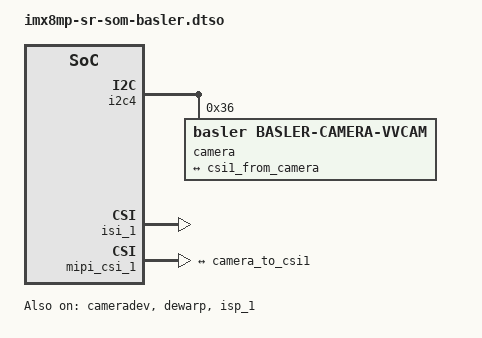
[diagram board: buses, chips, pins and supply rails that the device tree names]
// SPDX-License-Identifier: (GPL-2.0+ OR MIT)
/*
 * Copyright 2025 Josua Mayer <josua@solid-run.com>
 *
 * Overlay for Basler camera attached to SolidRun SoM camera connector.
 */

/dts-v1/;
/plugin/;

&i2c4 {
	#address-cells = <1>;
	#size-cells = <0>;

	camera@36 {
		compatible = "basler,basler-camera-vvcam";
		reg = <0x36>;
		csi_id = <0x01>;

		port {
			camera_to_csi1: endpoint {
				data-lanes = <1 2 3 4>;
				clock-lanes = <0>;
				link-frequencies = /bits/ 64 <750000000>;
				max-lane-frequency = /bits/ 64 <750000000>;
				max-pixel-frequency = /bits/ 64 <266000000>;
				max-data-rate = /bits/ 64 <0>;
				remote-endpoint = <&csi1_from_camera>;
			};
		};
	};
};

&cameradev {
	status = "okay";
};

&dewarp {
	status = "okay";
};

&isi_1 {
	status = "okay";

	m2m_device {
		status = "okay";
	};
};

&isp_1 {
	status = "okay";
};

&mipi_csi_1 {
	status = "okay";

	/*
	 * imx8-media-dev driver expects ports as direct sub-nodes,
	 * rather than below a parts node.
	 * Compare camera definition above for new style.
	 */
	port {
		csi1_from_camera: endpoint {
			remote-endpoint = <&camera_to_csi1>;
			data-lanes = <4>;
			csis-hs-settle = <16>;
		};
	};
};
